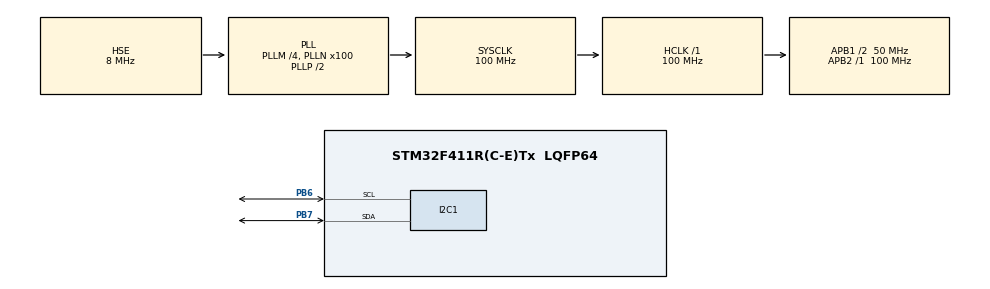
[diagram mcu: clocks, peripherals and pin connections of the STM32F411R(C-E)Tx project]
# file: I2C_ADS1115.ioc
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Mcu.Family=STM32F4
RCC.PLLSourceVirtual=RCC_PLLSOURCE_HSE
RCC.CortexFreq_Value=100000000
PH1\ -\ OSC_OUT.Mode=HSE-External-Oscillator
RCC.APB1CLKDivider=RCC_HCLK_DIV2
RCC.SYSCLKSource=RCC_SYSCLKSOURCE_PLLCLK
ProjectManager.StackSize=0x400
PA13.Signal=SYS_JTMS-SWDIO
PH0\ -\ OSC_IN.Mode=HSE-External-Oscillator
PH0\ -\ OSC_IN.Signal=RCC_OSC_IN
ProjectManager.TargetToolchain=MDK-ARM V5.27
RCC.HCLKFreq_Value=100000000
RCC.APB2TimFreq_Value=100000000
PB6.Signal=I2C1_SCL
PB6.Mode=I2C
RCC.AHBFreq_Value=100000000
RCC.HSE_VALUE=8000000
PH1\ -\ OSC_OUT.Signal=RCC_OSC_OUT
board=NUCLEO-F411RE
RCC.VCOOutputFreq_Value=200000000
RCC.APB2Freq_Value=100000000
PA14.Mode=Serial_Wire
PB7.Signal=I2C1_SDA
PA13.Mode=Serial_Wire
Mcu.Name=STM32F411R(C-E)Tx
RCC.FLatency-AdvancedSettings=FLASH_LATENCY_3
RCC.48MHZClocksFreq_Value=50000000
RCC.SYSCLKFreq_VALUE=100000000
Mcu.Package=LQFP64
PB7.Mode=I2C
PA14.Signal=SYS_JTCK-SWCLK
ProjectManager.HeapSize=0x200
RCC.HSI_VALUE=16000000
NVIC.PriorityGroup=NVIC_PRIORITYGROUP_0
RCC.PLLM=4
RCC.PLLN=100
RCC.APB1TimFreq_Value=100000000
RCC.APB1Freq_Value=50000000

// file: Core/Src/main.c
/* USER CODE BEGIN Header */
/**
  ******************************************************************************
  * @file           : main.c
  * @brief          : Main program body
  ******************************************************************************
  * @attention
  *
  * <h2><center>&copy; Copyright (c) 2020 STMicroelectronics.
  * All rights reserved.</center></h2>
  *
  * This software component is licensed by ST under BSD 3-Clause license,
  * the "License"; You may not use this file except in compliance with the
  * License. You may obtain a copy of the License at:
  *                        opensource.org/licenses/BSD-3-Clause
  *
  ******************************************************************************
  */
/* USER CODE END Header */
#include "main.h"

I2C_HandleTypeDef hi2c1;

void SystemClock_Config(void);
static void MX_GPIO_Init(void);
static void MX_I2C1_Init(void);
float read_ads1115(void);

/* USER CODE BEGIN 0 */
// #define addr 0X90;
//"unsigned char" close to "uint8_t" but they are not same ;
//static const uint8_t 0x90; //static: save the previous value
//volatile :if it use ,it can be change
unsigned char buffer[3];   /* max value : 255 => 1 1 1 1 1 1 1 1 */
unsigned char addr=0x90;  //char	8	-128	127 ;unsigned int	,16 or 32	,0,	65.535 or 4.294.967.295
float data=0;
float voltage=0;

/*working other topic;
char data1[10];
unsigned char data2[10];
static const uint8_t data3[10];
const char data4[10];
uint8_t data5[10];
static const char* data6 =" ";
*/
/* USER CODE END 0 */

int main(void)
{

  /* MCU Configuration--------------------------------------------------------*/

  /* Reset of all peripherals, Initializes the Flash interface and the Systick. */
  HAL_Init();

  /* Configure the system clock */
  SystemClock_Config();

  /* Initialize all configured peripherals */
  MX_GPIO_Init();
  MX_I2C1_Init();

  /* Infinite loop */
  while (1)
  {

    /* USER CODE BEGIN 3 */
		voltage=read_ads1115();
		//data degerini isleme sokucaz,voltaj degeri alinacak.
  }
  /* USER CODE END 3 */
}

void SystemClock_Config(void)
{
  RCC_OscInitTypeDef RCC_OscInitStruct = {0};
  RCC_ClkInitTypeDef RCC_ClkInitStruct = {0};

  /** Configure the main internal regulator output voltage
  */
  __HAL_RCC_PWR_CLK_ENABLE();
  __HAL_PWR_VOLTAGESCALING_CONFIG(PWR_REGULATOR_VOLTAGE_SCALE1);
  /** Initializes the RCC Oscillators according to the specified parameters
  * in the RCC_OscInitTypeDef structure.
  */
  RCC_OscInitStruct.OscillatorType = RCC_OSCILLATORTYPE_HSE;
  RCC_OscInitStruct.HSEState = RCC_HSE_ON;
  RCC_OscInitStruct.PLL.PLLState = RCC_PLL_ON;
  RCC_OscInitStruct.PLL.PLLSource = RCC_PLLSOURCE_HSE;
  RCC_OscInitStruct.PLL.PLLM = 4;
  RCC_OscInitStruct.PLL.PLLN = 100;
  RCC_OscInitStruct.PLL.PLLP = RCC_PLLP_DIV2;
  RCC_OscInitStruct.PLL.PLLQ = 4;
  if (HAL_RCC_OscConfig(&RCC_OscInitStruct) != HAL_OK)
  {
    Error_Handler();
  }
  /** Initializes the CPU, AHB and APB buses clocks
  */
  RCC_ClkInitStruct.ClockType = RCC_CLOCKTYPE_HCLK|RCC_CLOCKTYPE_SYSCLK
                              |RCC_CLOCKTYPE_PCLK1|RCC_CLOCKTYPE_PCLK2;
  RCC_ClkInitStruct.SYSCLKSource = RCC_SYSCLKSOURCE_PLLCLK;
  RCC_ClkInitStruct.AHBCLKDivider = RCC_SYSCLK_DIV1;
  RCC_ClkInitStruct.APB1CLKDivider = RCC_HCLK_DIV2;
  RCC_ClkInitStruct.APB2CLKDivider = RCC_HCLK_DIV1;

  if (HAL_RCC_ClockConfig(&RCC_ClkInitStruct, FLASH_LATENCY_3) != HAL_OK)
  {
    Error_Handler();
  }
}

static void MX_I2C1_Init(void)
{

  hi2c1.Instance = I2C1;
  hi2c1.Init.ClockSpeed = 100000;
  hi2c1.Init.DutyCycle = I2C_DUTYCYCLE_2;
  hi2c1.Init.OwnAddress1 = 0;
  hi2c1.Init.AddressingMode = I2C_ADDRESSINGMODE_7BIT;
  hi2c1.Init.DualAddressMode = I2C_DUALADDRESS_DISABLE;
  hi2c1.Init.OwnAddress2 = 0;
  hi2c1.Init.GeneralCallMode = I2C_GENERALCALL_DISABLE;
  hi2c1.Init.NoStretchMode = I2C_NOSTRETCH_DISABLE;
  if (HAL_I2C_Init(&hi2c1) != HAL_OK)
  {
    Error_Handler();
  }

}

static void MX_GPIO_Init(void)
{

  /* GPIO Ports Clock Enable */
  __HAL_RCC_GPIOH_CLK_ENABLE();
  __HAL_RCC_GPIOA_CLK_ENABLE();
  __HAL_RCC_GPIOB_CLK_ENABLE();

}

/* USER CODE BEGIN 4 */
float read_ads1115(void){
	buffer[0]=0x01;//config reg(read&write) was choosed for pointer. frame2
	buffer[1]=0XC2; //frame3
	buffer[2]=0x85;//or 83, frame4
	HAL_I2C_Master_Transmit(&hi2c1,addr,(uint8_t*)buffer,3,100);
	//We can write 0x48<<1 for adress
	//read
	buffer[0]=0x00;//conversion reg(only read) was choosed
	HAL_I2C_Master_Transmit(&hi2c1,addr,(uint8_t*)buffer,1,100);
	HAL_I2C_Master_Receive(&hi2c1,addr+1,(uint8_t*)buffer,2,100);
	data=(buffer[0]<<8)+buffer[1]; // we can use "+" or "|"
	return (float)0.125*(float)data; //+-4095 was choosed; 4096*2=8192; it is mapping 16 bite register, max deger for reg  2^16=65536;
// 8096/65536=0.125;
}

/* USER CODE END 4 */

void Error_Handler(void)
{
}

/************************ (C) COPYRIGHT STMicroelectronics *****END OF FILE****/
